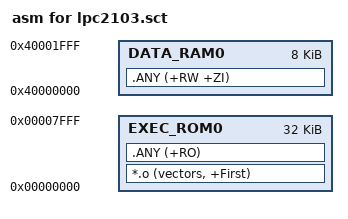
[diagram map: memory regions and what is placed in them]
; *************************************************************
; *** Scatter-Loading Description File generated by TKStudio***
; *************************************************************

LOAD_ROM0 0x00000000   ;Load region
{
EXEC_ROM0 0x00000000 0x00008000  ; load address = execution address
{
   *.o (vectors, +First)
   .ANY (+RO)
}
DATA_RAM0 0x40000000  0x00002000  ; RW DATA
{
   .ANY (+RW +ZI)
}
}
